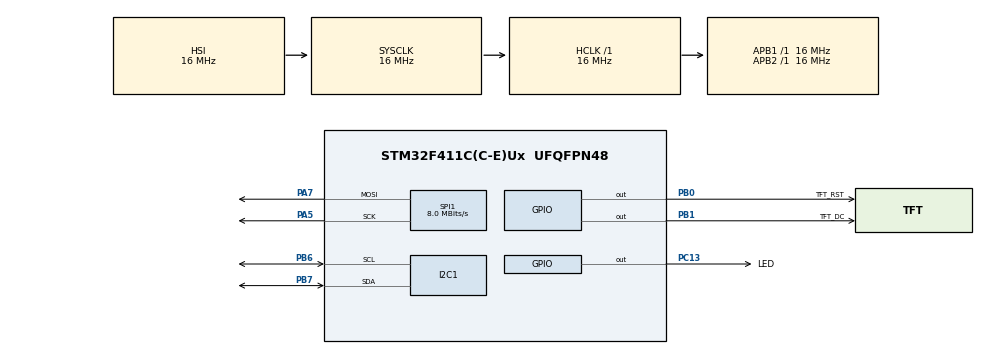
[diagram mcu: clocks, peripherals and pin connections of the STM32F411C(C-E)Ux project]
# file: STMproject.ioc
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Mcu.Family=STM32F4
Mcu.Name=STM32F411C(C-E)Ux
Mcu.Package=UFQFPN48
NVIC.PriorityGroup=NVIC_PRIORITYGROUP_4
PA13.Mode=Serial_Wire
PA13.Signal=SYS_JTMS-SWDIO
PA14.Mode=Serial_Wire
PA14.Signal=SYS_JTCK-SWCLK
PA5.Mode=TX_Only_Simplex_Unidirect_Master
PA5.Signal=SPI1_SCK
PA7.Mode=TX_Only_Simplex_Unidirect_Master
PA7.Signal=SPI1_MOSI
PB0.GPIO_Label=TFT_RST
PB0.PinState=GPIO_PIN_SET
PB0.Signal=GPIO_Output
PB1.GPIO_Label=TFT_DC
PB1.PinState=GPIO_PIN_SET
PB1.Signal=GPIO_Output
PB6.Mode=I2C
PB6.Signal=I2C1_SCL
PB7.Mode=I2C
PB7.Signal=I2C1_SDA
PC13-ANTI_TAMP.GPIO_Label=LED
PC13-ANTI_TAMP.PinState=GPIO_PIN_SET
PC13-ANTI_TAMP.Signal=GPIO_Output
ProjectManager.HeapSize=0x200
ProjectManager.StackSize=0x400
ProjectManager.TargetToolchain=CMake
RCC.AHBFreq_Value=16000000
RCC.APB1Freq_Value=16000000
RCC.APB2Freq_Value=16000000
RCC.CortexFreq_Value=16000000
RCC.HSE_VALUE=25000000
RCC.HSI_VALUE=16000000
RCC.LSE_VALUE=32768
RCC.SYSCLKFreq_VALUE=16000000
RCC.VCOOutputFreq_Value=192000000
SPI1.BaudRatePrescaler=SPI_BAUDRATEPRESCALER_2
SPI1.CLKPhase=SPI_PHASE_2EDGE
SPI1.CLKPolarity=SPI_POLARITY_HIGH
SPI1.CalculateBaudRate=8.0 MBits/s
SPI1.Direction=SPI_DIRECTION_2LINES
SPI1.Mode=SPI_MODE_MASTER
SPI1.VirtualType=VM_MASTER
board=custom

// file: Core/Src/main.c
/* USER CODE BEGIN Header */
/**
  ******************************************************************************
  * @file           : main.c
  * @brief          : Main program body
  ******************************************************************************
  * @attention
  *
  * Copyright (c) 2026 STMicroelectronics.
  * All rights reserved.
  *
  * This software is licensed under terms that can be found in the LICENSE file
  * in the root directory of this software component.
  * If no LICENSE file comes with this software, it is provided AS-IS.
  *
  ******************************************************************************
  */
/* USER CODE END Header */
#include "main.h"
/* USER CODE BEGIN Includes */
#include "i2c.h"
#include "spi.h"
#include "gpio.h"
#include "app.h"
/* USER CODE END Includes */

void SystemClock_Config(void);

int main(void)
{

  /* MCU Configuration--------------------------------------------------------*/

  /* Reset of all peripherals, Initializes the Flash interface and the Systick. */
  HAL_Init();

  /* Configure the system clock */
  SystemClock_Config();

  /* Initialize all configured peripherals */
  MX_GPIO_Init();
  MX_SPI1_Init();
  MX_I2C1_Init();
  /* USER CODE BEGIN 2 */
  App_Init();

  /* USER CODE END 2 */

  /* Infinite loop */
  while (1)
  {

    /* USER CODE BEGIN 3 */
    App_Process();
  }
  /* USER CODE END 3 */
}

void SystemClock_Config(void)
{
  RCC_OscInitTypeDef RCC_OscInitStruct = {0};
  RCC_ClkInitTypeDef RCC_ClkInitStruct = {0};

  /** Configure the main internal regulator output voltage
  */
  __HAL_RCC_PWR_CLK_ENABLE();
  __HAL_PWR_VOLTAGESCALING_CONFIG(PWR_REGULATOR_VOLTAGE_SCALE1);

  /** Initializes the RCC Oscillators according to the specified parameters
  * in the RCC_OscInitTypeDef structure.
  */
  RCC_OscInitStruct.OscillatorType = RCC_OSCILLATORTYPE_HSI;
  RCC_OscInitStruct.HSIState = RCC_HSI_ON;
  RCC_OscInitStruct.HSICalibrationValue = RCC_HSICALIBRATION_DEFAULT;
  RCC_OscInitStruct.PLL.PLLState = RCC_PLL_NONE;
  if (HAL_RCC_OscConfig(&RCC_OscInitStruct) != HAL_OK)
  {
    Error_Handler();
  }

  /** Initializes the CPU, AHB and APB buses clocks
  */
  RCC_ClkInitStruct.ClockType = RCC_CLOCKTYPE_HCLK|RCC_CLOCKTYPE_SYSCLK
                              |RCC_CLOCKTYPE_PCLK1|RCC_CLOCKTYPE_PCLK2;
  RCC_ClkInitStruct.SYSCLKSource = RCC_SYSCLKSOURCE_HSI;
  RCC_ClkInitStruct.AHBCLKDivider = RCC_SYSCLK_DIV1;
  RCC_ClkInitStruct.APB1CLKDivider = RCC_HCLK_DIV1;
  RCC_ClkInitStruct.APB2CLKDivider = RCC_HCLK_DIV1;

  if (HAL_RCC_ClockConfig(&RCC_ClkInitStruct, FLASH_LATENCY_0) != HAL_OK)
  {
    Error_Handler();
  }
}

void Error_Handler(void)
{
  __disable_irq();
  while (1)
  {
  }
}
